# CH643 register map
Vendor: WCH Ltd.; File version: 1.3
Registers are 32-bit, read-write, reset 0x0 unless marked. A register's access mark holds for its fields unless they carry their own. Offsets are from the block's base; [hi:lo] are bit positions.

## AWU — AWU configuration
Base 0x40026400
0x00 R16_AWU_CSR 16-bit — Status Control register
  [1] AWUEN — AWU Enable
0x04 R16_AWU_WR 16-bit reset 0x3F — AWU Window register
  [5:0] AWU_APR — AWU_APR value
0x08 R16_AWU_PSC 16-bit
  [3:0] AWU_TBR — AWU_TBR value

## OPA — OPA configuration
Base 0x40026000
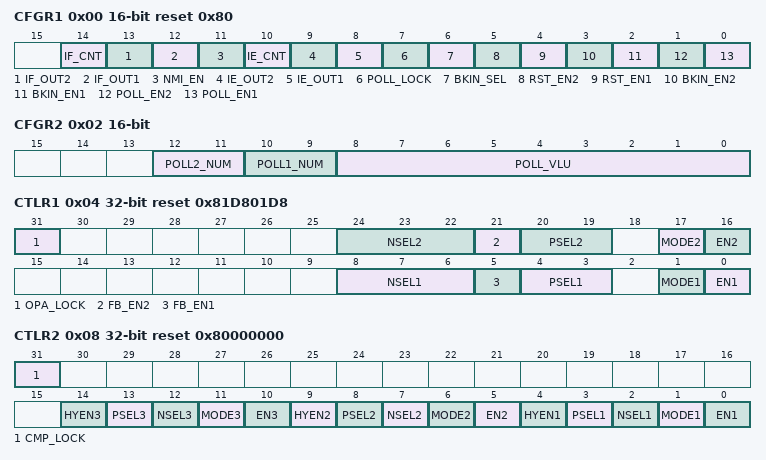
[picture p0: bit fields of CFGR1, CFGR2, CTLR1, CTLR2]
0x00 CFGR1 16-bit reset 0x80 — OPA Configuration register
  [14] IF_CNT — IF_CNT Configuration
  [13] IF_OUT2 — IF_OUT2 Enable
  [12] IF_OUT1 — IF_OUT1 Enable
  [11] NMI_EN — NMI_EN Enable
  [10] IE_CNT — IE_CNT Enable
  [9] IE_OUT2 — IE_OUT2 Enable
  [8] IE_OUT1 — IE_OUT1 Enable
  [7] POLL_LOCK — POLL_LOCK select
  [6] BKIN_SEL — BKIN_SEL select
  [5] RST_EN2 — RST_EN2 Enable
  [4] RST_EN1 — RST_EN1 Enable
  [3] BKIN_EN2 — BKIN_EN2 Enable
  [2] BKIN_EN1 — BKIN_EN1 Enable
  [1] POLL_EN2 — POLL_EN2 Enable
  [0] POLL_EN1 — POLL_EN1 Enable
0x02 CFGR2 16-bit access per field — OPA Configuration register
  [12:11] POLL2_NUM wo — POLL2_NUM Configuration
  [10:9] POLL1_NUM wo — POLL1_NUM Configuration
  [8:0] POLL_VLU rw — POLL_VLU Configuration
0x04 CTLR1 reset 0x81D801D8 — OPA Control1 register
  [31] OPA_LOCK
  [24:22] NSEL2 — output select
  [21] FB_EN2 — res inside enable
  [20:19] PSEL2 — Input select
  [17] MODE2 — OPA2 mode
  [16] EN2 — OPA2 enable
  [8:6] NSEL1 — output select
  [5] FB_EN1 — res inside enable
  [4:3] PSEL1 — Input select
  [1] MODE1 — OPA1 mode
  [0] EN1 — OPA1 enable
0x08 CTLR2 reset 0x80000000 — OPA Control2 register
  [31] CMP_LOCK
  [14] HYEN3 — CMP3 hysteresis comparator switch
  [13] PSEL3 — CMP3 IN_P Selection
  [12] NSEL3 — CMP3 IN_N Selection
  [11] MODE3 — CMP3 OUT Selection
  [10] EN3 — CMP3 Enable
  [9] HYEN2 — CMP2 hysteresis comparator switch
  [8] PSEL2 — CMP2 IN_P Selection
  [7] NSEL2 — CMP2 IN_N Selection
  [6] MODE2 — CMP2 OUT Selection
  [5] EN2 — CMP2 Enable
  [4] HYEN1 — CMP1 hysteresis comparator switch
  [3] PSEL1 — CMP1 IN_P Selection
  [2] NSEL1 — CMP1 IN_N Selection
  [1] MODE1 — CMP1 OUT Selection
  [0] EN1 — CMP1 Enable
0x0C OPA_KEY — OPA unlock key register
  [31:0] OPA_KEY — OPA_KEY value
0x10 CMP_KEY — CMP unlock key register
  [31:0] CMP_KEY — CMP_KEY value
0x14 POLL_KEY — POLL unlock key register
  [31:0] POLL_KEY — POLL_KEY value

## ESIG — ESIG configuration
Base 0x1FFFF7E0
0x00 FLACAP 16-bit ro — Flash capecity register
  [15:0] F_SIZE — F_SIZE/kByte
0x08 UNIID1 ro — UID register
  [31:0] U_ID — U_ID value
0x0C UNIID2 ro — UID register
  [31:0] U_ID — U_ID value
0x10 UNIID3 ro — Div register
  [31:0] AWU_APR — AWU_APR value

## USBPD — USBPD configuration
Base 0x40027000
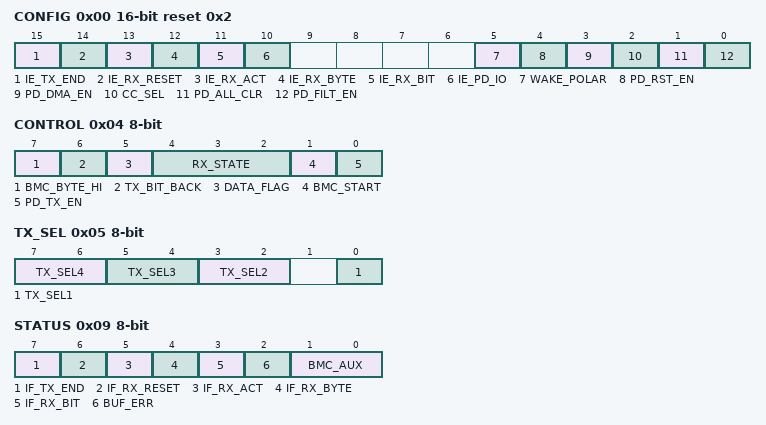
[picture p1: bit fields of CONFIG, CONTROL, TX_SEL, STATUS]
0x00 CONFIG 16-bit reset 0x2 — PD interrupt enable register
  [15] IE_TX_END — transfer complete register
  [14] IE_RX_RESET — Receive complete rst register
  [13] IE_RX_ACT — Receive complete register
  [12] IE_RX_BYTE — Receive byte register
  [11] IE_RX_BIT — bit interrupt Enable
  [10] IE_PD_IO — IO Enable
  [5] WAKE_POLAR — wakeup polarity
  [4] PD_RST_EN — PD RST Enable
  [3] PD_DMA_EN — PD DMA Enable
  [2] CC_SEL — PD Commutation port
  [1] PD_ALL_CLR — PD ITClear
  [0] PD_FILT_EN — control PD pin input filter enable
0x02 BMC_CLK_CNT 16-bit — BMC sampling clock counter
  [8:0] BMC_CLK_CNT — R/T counter
0x04 CONTROL 8-bit access per field — PD Send and receive enable register
  [7] BMC_BYTE_HI ro — BMC_BYTE_HI value
  [6] TX_BIT_BACK ro — TX_BIT_BACK value
  [5] DATA_FLAG ro — DATA_FLAG value
  [4:2] RX_STATE rw — PD receive status identification
  [1] BMC_START rw — BMC_START value
  [0] PD_TX_EN rw — PD_TX_EN value
0x05 TX_SEL 8-bit — SOP port selection register
  [7:6] TX_SEL4 — TX_SEL4 value
  [5:4] TX_SEL3 — TX_SEL3 value
  [3:2] TX_SEL2 — TX_SEL2 value
  [0] TX_SEL1 — TX_SEL1 value
0x06 BMC_TX_SZ 16-bit — PD send length register
  [8:0] BMC_TX_SZ — BMC_TX_SZ value
0x08 DATA_BUF 8-bit ro — DMA cache data register
  [7:0] DATA_BUF — DATA_BUF value
0x09 STATUS 8-bit access per field — PD interrupt flag register
  [7] IF_TX_END rw — IF_TX_END value
  [6] IF_RX_RESET rw — IF_RX_RESET value
  [5] IF_RX_ACT rw — IF_RX_ACT value
  [4] IF_RX_BYTE rw — IF_RX_BYTE value
  [3] IF_RX_BIT rw — IF_RX_BIT value
  [2] BUF_ERR rw — BUF_ERR value
  [1:0] BMC_AUX ro — BMC_AUX value
0x0A BMC_BYTE_CNT 16-bit ro — Byte counter
  [8:0] BMC_BYTE_CNT — BMC_BYTE_CNT value
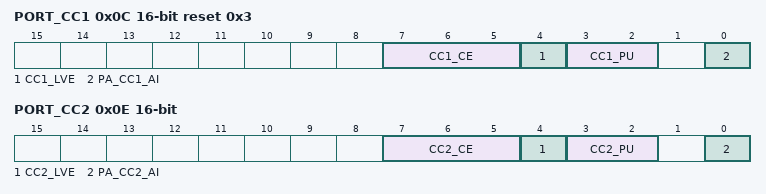
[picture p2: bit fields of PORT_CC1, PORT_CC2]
0x0C PORT_CC1 16-bit access per field reset 0x3 — CC1 port control register
  [7:5] CC1_CE rw — CC1_CE value
  [4] CC1_LVE rw — CC1_LVE value
  [3:2] CC1_PU rw — CC1_PU value
  [0] PA_CC1_AI ro — PA_CC1_AI value
0x0E PORT_CC2 16-bit — CC2 port control register
  [7:5] CC2_CE — CC2_CE value
  [4] CC2_LVE — CC2_LVE value
  [3:2] CC2_PU — CC2_PU value
  [0] PA_CC2_AI — PA_CC2_AI value
0x10 DMA 16-bit — PD buffer start address register
  [15:0] USBPD_DMA_ADDR — USBPD_DMA_ADDR value

## LEDPWM — LEDPWM configuration
Base 0x40026800
0x00 LED_COM_SEL 8-bit — LED row driver COM select register
  [5:0] COM_SEL
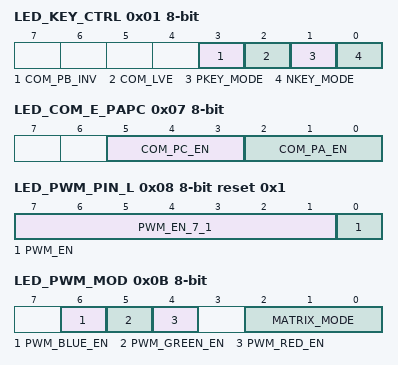
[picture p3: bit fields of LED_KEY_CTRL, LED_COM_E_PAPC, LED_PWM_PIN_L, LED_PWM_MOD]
0x01 LED_KEY_CTRL 8-bit — LED keyboard control register
  [3] COM_PB_INV — PB invert enable
  [2] COM_LVE — LOW Voltage enable
  [1] PKEY_MODE — PMOS diode key enable
  [0] NKEY_MODE — NMOS diode key enable
0x02 LED_PWM_OE 8-bit — The LED column drives the PWM global enable register
  [0] PWM_OE — LED PWM Enable
0x03 LED_DMA_CNT 8-bit — LED DMA data counter register
  [4:0] DMA_CNT — DMA Counter
0x04 LED_COM_E_PB_L 8-bit — PB[7:0] pin COM enable register
  [7:0] COM_E_PB_L — PB[7:0] COM Driver Enable
0x05 LED_COM_E_PB_M 8-bit — PB[15:8] pin COM enable register
  [7:0] COM_E_PB_M — PB[15:8] COM Driver Enable
0x06 LED_COM_E_PB_H 8-bit — PB[23:16] pin COM enable register
  [7:0] COM_E_PB_H — PB[23:16] COM Driver Enable
0x07 LED_COM_E_PAPC 8-bit — PA/PC pin COM enable register
  [5:3] COM_PC_EN — PC COM Driver enable
  [2:0] COM_PA_EN — PA COM Driver enable
0x08 LED_PWM_PIN_L 8-bit reset 0x1 — The LED lower 8 columns drive the PWM enable register
  [7:1] PWM_EN_7_1 — LED PWM[7:1] Enable
  [0] PWM_EN — LED PWM_0 Enable
0x09 LED_PWM_PIN_H 8-bit — LED high 8 columns drive the PWM enable register
  [7:0] PWM_EN — LED[15:8] enable
0x0B LED_PWM_MOD 8-bit — LED PWM mode register
  [6] PWM_BLUE_EN — BLUE PWM Enable
  [5] PWM_GREEN_EN — Green PWM Enable
  [4] PWM_RED_EN — RED PWM Enable
  [2:0] MATRIX_MODE — MATRIX_MODE Select
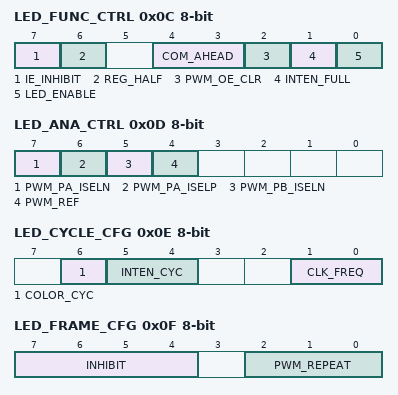
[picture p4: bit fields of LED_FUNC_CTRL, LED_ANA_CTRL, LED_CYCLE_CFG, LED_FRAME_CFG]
0x0C LED_FUNC_CTRL 8-bit — LED function control register
  [7] IE_INHIBIT — interrupt Enable
  [6] REG_HALF — RED Brightness mode
  [4:3] COM_AHEAD — COM Output Select
  [2] PWM_OE_CLR — Automatic Clear PWM-Enable
  [1] INTEN_FULL — Forced Output
  [0] LED_ENABLE
0x0D LED_ANA_CTRL 8-bit — LED analog control register
  [7] PWM_PA_ISELN — PA NMOS Constant current mode enable
  [6] PWM_PA_ISELP — PA PMOS Constant current mode enable
  [5] PWM_PB_ISELN — PB NMOS Constant current mode enable
  [4] PWM_REF — PWM Constant current mode enable
0x0E LED_CYCLE_CFG 8-bit — LED cycle configuration register
  [6] COLOR_CYC — PWM-Color cycle
  [5:4] INTEN_CYC — PWM-Brightness cycle
  [1:0] CLK_FREQ — LED frequency select
0x0F LED_FRAME_CFG 8-bit — LED frame configuration register
  [7:4] INHIBIT — INHIBIT Window value
  [2:0] PWM_REPEAT — PWM_REPEAT times
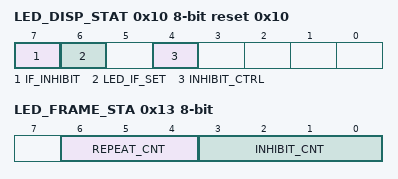
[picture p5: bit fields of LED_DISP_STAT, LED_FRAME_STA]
0x10 LED_DISP_STAT 8-bit access per field reset 0x10 — LED display status register
  [7] IF_INHIBIT rw — INHIBIT Interrupt Flag
  [6] LED_IF_SET wo
  [4] INHIBIT_CTRL ro — Forbidden Control
0x11 LED_INTEN_CNT 8-bit ro — LED brightness PWM counting register
  [7:0] INTEN_CNT — PWM_Strength Counter
0x12 LED_COLOR_CNT 8-bit ro — LED color PWM counting register
  [7:0] COLOR_CNT — PWM_Color Counter
0x13 LED_FRAME_STA 8-bit ro — LED frame status register
  [6:4] REPEAT_CNT — PWM_REPEAT Counter
  [3:0] INHIBIT_CNT — Forbidden Counter
0x14 LED_INTEN_ADJ 8-bit — LED brightness adjustment register
  [7:0] INTEN_ADJ — LED Strength adjust
0x15 LED_RED_ADJ 8-bit — LED red adjustment register
  [7:0] RED_ADJ — Red LED Strength adjust
0x16 LED_GREEN_ADJ 8-bit — LED green adjustment register
  [7:0] GREEN_ADJ — Green LED Strength adjust
0x17 LED_BLUE_ADJ 8-bit — LED blue adjustment register
  [7:0] BLUE_ADJ_7_0 — Blue LED Strength adjust
0x18 LED_DMA 16-bit — DMA buffer current address register
  [15:0] DMA — Cache DMA Address Buffer
